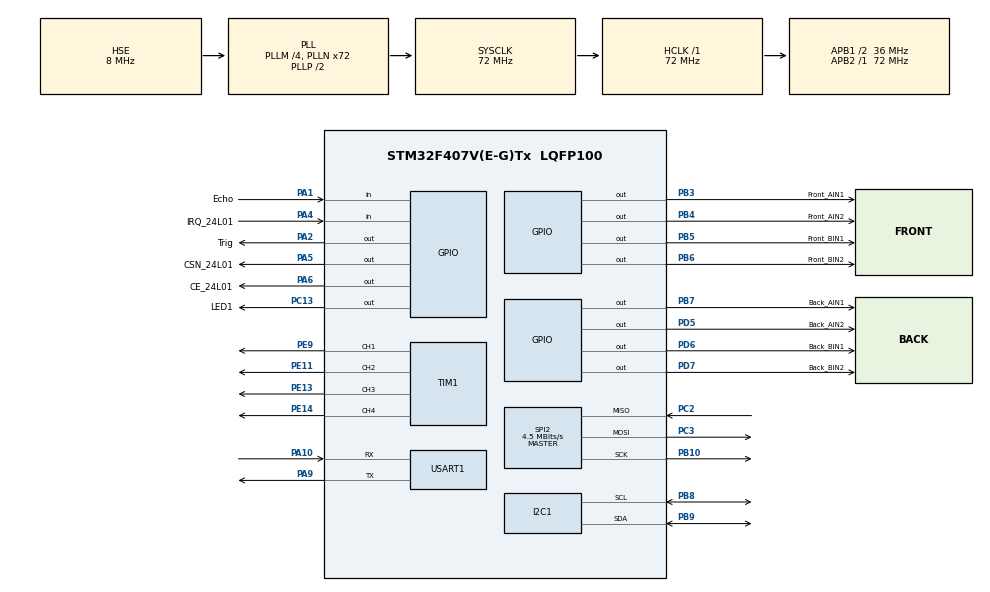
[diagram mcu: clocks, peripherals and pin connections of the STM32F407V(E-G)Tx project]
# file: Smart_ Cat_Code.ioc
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Mcu.Family=STM32F4
Mcu.Name=STM32F407V(E-G)Tx
Mcu.Package=LQFP100
NVIC.PriorityGroup=NVIC_PRIORITYGROUP_4
PA1.GPIO_Label=Echo
PA1.Signal=GPIO_Input
PA10.Mode=Asynchronous
PA10.Signal=USART1_RX
PA2.GPIO_Label=Trig
PA2.GPIO_PuPd=GPIO_PULLDOWN
PA2.Signal=GPIO_Output
PA4.GPIO_Label=IRQ_24L01
PA4.GPIO_PuPd=GPIO_PULLUP
PA4.Signal=GPIO_Input
PA5.GPIO_Label=CSN_24L01
PA5.GPIO_Speed=GPIO_SPEED_FREQ_HIGH
PA5.PinState=GPIO_PIN_SET
PA5.Signal=GPIO_Output
PA6.GPIO_Label=CE_24L01
PA6.GPIO_Speed=GPIO_SPEED_FREQ_HIGH
PA6.PinState=GPIO_PIN_SET
PA6.Signal=GPIO_Output
PA9.Mode=Asynchronous
PA9.Signal=USART1_TX
PB10.Mode=Full_Duplex_Master
PB10.Signal=SPI2_SCK
PB3.GPIO_Label=Front_AIN1
PB3.Signal=GPIO_Output
PB4.GPIO_Label=Front_AIN2
PB4.Signal=GPIO_Output
PB5.GPIO_Label=Front_BIN1
PB5.Signal=GPIO_Output
PB6.GPIO_Label=Front_BIN2
PB6.Signal=GPIO_Output
PB7.GPIO_Label=Back_AIN1
PB7.Signal=GPIO_Output
PB8.Mode=I2C
PB8.Signal=I2C1_SCL
PB9.Mode=I2C
PB9.Signal=I2C1_SDA
PC13-ANTI_TAMP.GPIO_Label=LED1
PC13-ANTI_TAMP.Signal=GPIO_Output
PC14-OSC32_IN.Mode=LSE-External-Oscillator
PC14-OSC32_IN.Signal=RCC_OSC32_IN
PC15-OSC32_OUT.Mode=LSE-External-Oscillator
PC15-OSC32_OUT.Signal=RCC_OSC32_OUT
PC2.Mode=Full_Duplex_Master
PC2.Signal=SPI2_MISO
PC3.Mode=Full_Duplex_Master
PC3.Signal=SPI2_MOSI
PD5.GPIO_Label=Back_AIN2
PD5.Signal=GPIO_Output
PD6.GPIO_Label=Back_BIN1
PD6.Signal=GPIO_Output
PD7.GPIO_Label=Back_BIN2
PD7.Signal=GPIO_Output
PE11.Signal=S_TIM1_CH2
PE13.Signal=S_TIM1_CH3
PE14.Signal=S_TIM1_CH4
PE9.Signal=S_TIM1_CH1
PH0-OSC_IN.Mode=HSE-External-Oscillator
PH0-OSC_IN.Signal=RCC_OSC_IN
PH1-OSC_OUT.Mode=HSE-External-Oscillator
PH1-OSC_OUT.Signal=RCC_OSC_OUT
ProjectManager.HeapSize=0x200
ProjectManager.StackSize=0x400
ProjectManager.TargetToolchain=MDK-ARM V5.32
RCC.48MHZClocksFreq_Value=36000000
RCC.AHBFreq_Value=72000000
RCC.APB1CLKDivider=RCC_HCLK_DIV2
RCC.APB1Freq_Value=36000000
RCC.APB1TimFreq_Value=72000000
RCC.APB2Freq_Value=72000000
RCC.APB2TimFreq_Value=72000000
RCC.CortexFreq_Value=72000000
RCC.HCLKFreq_Value=72000000
RCC.HSE_VALUE=8000000
RCC.HSI_VALUE=16000000
RCC.PLLM=4
RCC.PLLN=72
RCC.PLLSourceVirtual=RCC_PLLSOURCE_HSE
RCC.SYSCLKFreq_VALUE=72000000
RCC.SYSCLKSource=RCC_SYSCLKSOURCE_PLLCLK
RCC.VCOOutputFreq_Value=144000000
SH.S_TIM1_CH1.0=TIM1_CH1,PWM Generation1 CH1
SH.S_TIM1_CH2.0=TIM1_CH2,PWM Generation2 CH2
SH.S_TIM1_CH3.0=TIM1_CH3,PWM Generation3 CH3
SH.S_TIM1_CH4.0=TIM1_CH4,PWM Generation4 CH4
SPI2.BaudRatePrescaler=SPI_BAUDRATEPRESCALER_8
SPI2.CalculateBaudRate=4.5 MBits/s
SPI2.Direction=SPI_DIRECTION_2LINES
SPI2.Mode=SPI_MODE_MASTER
SPI2.VirtualType=VM_MASTER
TIM1.Channel-PWM\ Generation1\ CH1=TIM_CHANNEL_1
TIM1.Channel-PWM\ Generation2\ CH2=TIM_CHANNEL_2
TIM1.Channel-PWM\ Generation3\ CH3=TIM_CHANNEL_3
TIM1.Channel-PWM\ Generation4\ CH4=TIM_CHANNEL_4
TIM6.Prescaler=71
USART1.VirtualMode=VM_ASYNC
VP_TIM6_VS_ClockSourceINT.Mode=Enable_Timer
board=custom

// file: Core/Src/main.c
/* USER CODE BEGIN Header */
/**
 ******************************************************************************
 * @file           : main.c
 * @brief          : Main program body
 ******************************************************************************
 * @attention
 *
 * Copyright (c) 2024 STMicroelectronics.
 * All rights reserved.
 *
 * This software is licensed under terms that can be found in the LICENSE file
 * in the root directory of this software component.
 * If no LICENSE file comes with this software, it is provided AS-IS.
 *
 ******************************************************************************
 */
/* USER CODE END Header */
#include "main.h"
#include "i2c.h"
#include "spi.h"
#include "tim.h"
#include "usart.h"
#include "gpio.h"

/* USER CODE BEGIN Includes */
#include "../../User/Inc/motor.h"
#include "../../User/Inc/HC_SR04.h"

/* USER CODE END Includes */

void SystemClock_Config(void);

int main(void)
{

  /* MCU Configuration--------------------------------------------------------*/

  /* Reset of all peripherals, Initializes the Flash interface and the Systick. */
  HAL_Init();

  /* Configure the system clock */
  SystemClock_Config();

  /* Initialize all configured peripherals */
  MX_GPIO_Init();
  MX_TIM1_Init();
  MX_I2C1_Init();
  MX_SPI2_Init();
  MX_USART1_UART_Init();
  MX_TIM6_Init();
  /* USER CODE BEGIN 2 */
  HAL_UART_Receive_IT(&huart1, (uint8_t *)&USART1_NewData, 1);
  // 设置 PWM
  HAL_TIM_PWM_Start(&htim1, TIM_CHANNEL_1);
  HAL_TIM_PWM_Start(&htim1, TIM_CHANNEL_2);
  HAL_TIM_PWM_Start(&htim1, TIM_CHANNEL_3);
  HAL_TIM_PWM_Start(&htim1, TIM_CHANNEL_4);
  int SPEED = 4000;
  int increment = 100;

  /* USER CODE END 2 */

  /* Infinite loop */
  /* USER CODE BEGIN WHILE */
  while (1)
  {
    HC_SR04_Start();

    // SPEED += increment;
    // if (SPEED == 8400 || SPEED == 0)
    // {
    //   increment = -increment;
    // }
    // HAL_Delay(100);
    // Set_Speed(SPEED);
    // Directional_Control(Directional_Front);

    // HAL_Delay(1000);
    // Set_Pwm(Front_Left, SPEED);
    // HAL_Delay(1000);
    // Set_Pwm(Front_Left, 0);

    // HAL_Delay(1000);
    // Set_Pwm(Front_Right, SPEED);
    // HAL_Delay(1000);
    // Set_Pwm(Front_Right, 0);

    // HAL_Delay(1000);
    // Set_Pwm(Back_Left, SPEED);
    // HAL_Delay(1000);
    // Set_Pwm(Back_Left, 0);

    // HAL_Delay(1000);
    // Set_Pwm(Back_Right, SPEED);
    // HAL_Delay(1000);
    // Set_Pwm(Back_Right, 0);

    /* USER CODE END WHILE */

  }
}

void SystemClock_Config(void)
{
  RCC_OscInitTypeDef RCC_OscInitStruct = {0};
  RCC_ClkInitTypeDef RCC_ClkInitStruct = {0};

  /** Configure the main internal regulator output voltage
   */
  __HAL_RCC_PWR_CLK_ENABLE();
  __HAL_PWR_VOLTAGESCALING_CONFIG(PWR_REGULATOR_VOLTAGE_SCALE1);

  /** Initializes the RCC Oscillators according to the specified parameters
   * in the RCC_OscInitTypeDef structure.
   */
  RCC_OscInitStruct.OscillatorType = RCC_OSCILLATORTYPE_HSE;
  RCC_OscInitStruct.HSEState = RCC_HSE_ON;
  RCC_OscInitStruct.PLL.PLLState = RCC_PLL_ON;
  RCC_OscInitStruct.PLL.PLLSource = RCC_PLLSOURCE_HSE;
  RCC_OscInitStruct.PLL.PLLM = 4;
  RCC_OscInitStruct.PLL.PLLN = 72;
  RCC_OscInitStruct.PLL.PLLP = RCC_PLLP_DIV2;
  RCC_OscInitStruct.PLL.PLLQ = 4;
  if (HAL_RCC_OscConfig(&RCC_OscInitStruct) != HAL_OK)
  {
    Error_Handler();
  }

  /** Initializes the CPU, AHB and APB buses clocks
   */
  RCC_ClkInitStruct.ClockType = RCC_CLOCKTYPE_HCLK | RCC_CLOCKTYPE_SYSCLK | RCC_CLOCKTYPE_PCLK1 | RCC_CLOCKTYPE_PCLK2;
  RCC_ClkInitStruct.SYSCLKSource = RCC_SYSCLKSOURCE_PLLCLK;
  RCC_ClkInitStruct.AHBCLKDivider = RCC_SYSCLK_DIV1;
  RCC_ClkInitStruct.APB1CLKDivider = RCC_HCLK_DIV2;
  RCC_ClkInitStruct.APB2CLKDivider = RCC_HCLK_DIV1;

  if (HAL_RCC_ClockConfig(&RCC_ClkInitStruct, FLASH_LATENCY_2) != HAL_OK)
  {
    Error_Handler();
  }
}

void Error_Handler(void)
{
  __disable_irq();
  while (1)
  {
  }
}
